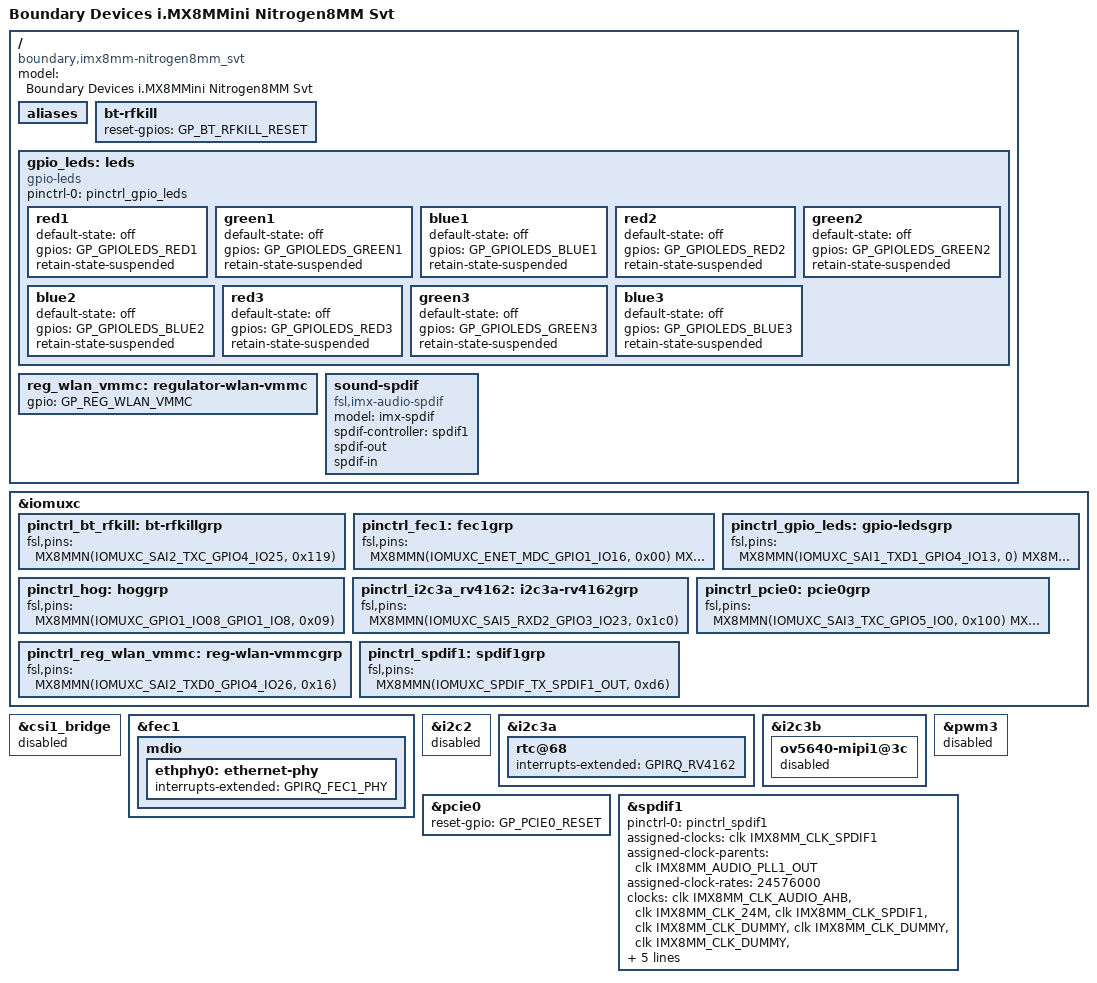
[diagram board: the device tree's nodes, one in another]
// SPDX-License-Identifier: (GPL-2.0+ OR MIT)
/*
 * Copyright 2022 Boundary Devices
 */
#define TOUCHSCREEN_I2C_BUS	i2c3b
#include "imx8mm-nitrogen8mm.dts"

&iomuxc {
	/delete-node/ ecspi2-mcp2515tgrp;

	pinctrl_bt_rfkill: bt-rfkillgrp {
		fsl,pins = <
#undef GP_BT_RFKILL_RESET
#define GP_BT_RFKILL_RESET	<&gpio4 25 GPIO_ACTIVE_LOW>
			MX8MMN(IOMUXC_SAI2_TXC_GPIO4_IO25, 0x119)
		>;
	};

	pinctrl_fec1: fec1grp {
		fsl,pins = <
			/* PAD_CTL_ODE is screwy on 8mm mini, avoid it */
#define GP_MII_MDC	<&gpio1 16 GPIO_PULSE_HIGH>
			MX8MMN(IOMUXC_ENET_MDC_GPIO1_IO16, 0x00)
#define GP_MII_MDIO	<&gpio1 17 GPIO_ACTIVE_HIGH>
			MX8MMN(IOMUXC_ENET_MDIO_GPIO1_IO17, 0x00)
			MX8MMN(IOMUXC_ENET_RD0_ENET1_RGMII_RD0, 0x91)
			MX8MMN(IOMUXC_ENET_RD1_ENET1_RGMII_RD1, 0x91)
			MX8MMN(IOMUXC_ENET_RD2_ENET1_RGMII_RD2, 0x91)
			MX8MMN(IOMUXC_ENET_RD3_ENET1_RGMII_RD3, 0x91)
			MX8MMN(IOMUXC_ENET_RXC_ENET1_RGMII_RXC, 0x91)
			MX8MMN(IOMUXC_ENET_RX_CTL_ENET1_RGMII_RX_CTL, 0x91)
			MX8MMN(IOMUXC_ENET_TD0_ENET1_RGMII_TD0, 0x1f)
			MX8MMN(IOMUXC_ENET_TD1_ENET1_RGMII_TD1, 0x1f)
			MX8MMN(IOMUXC_ENET_TD2_ENET1_RGMII_TD2, 0x1f)
			MX8MMN(IOMUXC_ENET_TD3_ENET1_RGMII_TD3, 0x1f)
			MX8MMN(IOMUXC_ENET_TXC_ENET1_RGMII_TXC, 0x1f)
			MX8MMN(IOMUXC_ENET_TX_CTL_ENET1_RGMII_TX_CTL, 0x1f)
			MX8MMN(IOMUXC_SAI3_TXFS_GPT1_CAPTURE2, 0x0)
			MX8MMN(IOMUXC_I2C2_SDA_ENET1_1588_EVENT1_OUT, 0x0)
#undef GP_FEC1_RESET
#define GP_FEC1_RESET	<&gpio1 3 GPIO_ACTIVE_LOW>
			MX8MMN(IOMUXC_GPIO1_IO03_GPIO1_IO3, 0x159)
#undef GPIRQ_FEC1_PHY
#define GPIRQ_FEC1_PHY	<&gpio1 5 IRQ_TYPE_LEVEL_LOW>
			MX8MMN(IOMUXC_GPIO1_IO05_GPIO1_IO5, 0x159)
		>;
	};

	pinctrl_gpio_leds: gpio-ledsgrp {
	        fsl,pins = <
#define GP_GPIOLEDS_RED1        <&gpio4 13 (GPIO_OPEN_DRAIN | GPIO_ACTIVE_LOW)>
	                MX8MMN(IOMUXC_SAI1_TXD1_GPIO4_IO13, 0)
#define GP_GPIOLEDS_GREEN1      <&gpio4 14 (GPIO_OPEN_DRAIN | GPIO_ACTIVE_LOW)>
	                MX8MMN(IOMUXC_SAI1_TXD2_GPIO4_IO14, 0)
#define GP_GPIOLEDS_BLUE1       <&gpio4 15 (GPIO_OPEN_DRAIN | GPIO_ACTIVE_LOW)>
	                MX8MMN(IOMUXC_SAI1_TXD3_GPIO4_IO15, 0)

#define GP_GPIOLEDS_RED2        <&gpio4 16 (GPIO_OPEN_DRAIN | GPIO_ACTIVE_LOW)>
	                MX8MMN(IOMUXC_SAI1_TXD4_GPIO4_IO16, 0)
#define GP_GPIOLEDS_GREEN2      <&gpio4 17 (GPIO_OPEN_DRAIN | GPIO_ACTIVE_LOW)>
	                MX8MMN(IOMUXC_SAI1_TXD5_GPIO4_IO17, 0)
#define GP_GPIOLEDS_BLUE2       <&gpio4 18 (GPIO_OPEN_DRAIN | GPIO_ACTIVE_LOW)>
	                MX8MMN(IOMUXC_SAI1_TXD6_GPIO4_IO18, 0)

#define GP_GPIOLEDS_RED3        <&gpio4 19 (GPIO_OPEN_DRAIN | GPIO_ACTIVE_LOW)>
	                MX8MMN(IOMUXC_SAI1_TXD7_GPIO4_IO19, 0)
#define GP_GPIOLEDS_GREEN3      <&gpio4 0 (GPIO_OPEN_DRAIN | GPIO_ACTIVE_LOW)>
	                MX8MMN(IOMUXC_SAI1_RXFS_GPIO4_IO0, 0)
#define GP_GPIOLEDS_BLUE3       <&gpio4 1 (GPIO_OPEN_DRAIN | GPIO_ACTIVE_LOW)>
	                MX8MMN(IOMUXC_SAI1_RXC_GPIO4_IO1, 0)
	        >;
	};

	pinctrl_hog: hoggrp {
		fsl,pins = <
			MX8MMN(IOMUXC_GPIO1_IO08_GPIO1_IO8, 0x09)
		>;
	};

	pinctrl_i2c3a_rv4162: i2c3a-rv4162grp {
		fsl,pins = <
#undef GPIRQ_RV4162
#define GPIRQ_RV4162		<&gpio3 23 IRQ_TYPE_LEVEL_LOW>
			MX8MMN(IOMUXC_SAI5_RXD2_GPIO3_IO23, 0x1c0)
		>;
	};

	pinctrl_pcie0: pcie0grp {
		fsl,pins = <
#undef GP_PCIE0_RESET
#define GP_PCIE0_RESET		<&gpio5 0 GPIO_ACTIVE_LOW>
			MX8MMN(IOMUXC_SAI3_TXC_GPIO5_IO0, 0x100)
#define GP_PCIE0_DISABLE	<&gpio1 4 GPIO_ACTIVE_LOW>
			MX8MMN(IOMUXC_GPIO1_IO04_GPIO1_IO4, 0x100)
		>;
	};

	pinctrl_reg_wlan_vmmc: reg-wlan-vmmcgrp {
		fsl,pins = <
#undef GP_REG_WLAN_VMMC
#define GP_REG_WLAN_VMMC	<&gpio4 26 GPIO_ACTIVE_HIGH>
			MX8MMN(IOMUXC_SAI2_TXD0_GPIO4_IO26, 0x16)
		>;
	};

	/delete-node/ sai2grp;
	/delete-node/ sai5grp;

	pinctrl_spdif1: spdif1grp {
		fsl,pins = <
			MX8MMN(IOMUXC_SPDIF_TX_SPDIF1_OUT, 0xd6)
		>;
	};
};

/ {
	model = "Boundary Devices i.MX8MMini Nitrogen8MM Svt";
	compatible = "boundary,imx8mm-nitrogen8mm_svt", "fsl,imx8mm";

	aliases {
		/delete-property/ sai2;
		/delete-property/ sai5;
		/delete-property/ spi1;
	};

	bt-rfkill {
		reset-gpios = GP_BT_RFKILL_RESET;
	};

	gpio_leds: leds {
                compatible = "gpio-leds";
                pinctrl-names = "default";
                pinctrl-0 = <&pinctrl_gpio_leds>;

                red1 {
                        default-state = "off";
                        gpios = GP_GPIOLEDS_RED1;
                        retain-state-suspended;
                };

                green1 {
                        default-state = "off";
                        gpios = GP_GPIOLEDS_GREEN1;
                        retain-state-suspended;
                };

                blue1 {
                        default-state = "off";
                        gpios = GP_GPIOLEDS_BLUE1;
                        retain-state-suspended;
                };

                red2 {
                        default-state = "off";
                        gpios = GP_GPIOLEDS_RED2;
                        retain-state-suspended;
                };

                green2 {
                        default-state = "off";
                        gpios = GP_GPIOLEDS_GREEN2;
                        retain-state-suspended;
                };

                blue2 {
                        default-state = "off";
                        gpios = GP_GPIOLEDS_BLUE2;
                        retain-state-suspended;
                };

                red3 {
                        default-state = "off";
                        gpios = GP_GPIOLEDS_RED3;
                        retain-state-suspended;
                };

                green3 {
                        default-state = "off";
                        gpios = GP_GPIOLEDS_GREEN3;
                        retain-state-suspended;
                };

                blue3 {
                        default-state = "off";
                        gpios = GP_GPIOLEDS_BLUE3;
                        retain-state-suspended;
		};
	};

	reg_wlan_vmmc: regulator-wlan-vmmc {
		gpio = GP_REG_WLAN_VMMC;
	};

	sound-spdif {
		compatible = "fsl,imx-audio-spdif";
		model = "imx-spdif";
		spdif-controller = <&spdif1>;
		spdif-out;
		spdif-in;
	};
};

&csi1_bridge {
	status = "disabled";
};

/delete-node/ &ecspi2;

&fec1 {
#if 0
	phy-reset-gpios = GP_FEC1_RESET;
#endif

	mdio {
		ethphy0: ethernet-phy {
			interrupts-extended = GPIRQ_FEC1_PHY;
		};
	};
};

&i2c2 {
	status = "disabled";
};

&i2c3a {
	rtc@68 {
		interrupts-extended = GPIRQ_RV4162;
	};
};

&i2c3b {
	ov5640-mipi1@3c {
		status = "disabled";
	};
};

&pcie0 {
	reset-gpio = GP_PCIE0_RESET;
};

&pwm3 {
	status = "disabled";
};

/delete-node/ &sai2;
/delete-node/ &sai5;

&spdif1 {
	pinctrl-names = "default";
	pinctrl-0 = <&pinctrl_spdif1>;
	assigned-clocks = <&clk IMX8MM_CLK_SPDIF1>;
	assigned-clock-parents = <&clk IMX8MM_AUDIO_PLL1_OUT>;
	assigned-clock-rates = <24576000>;
	clocks = <&clk IMX8MM_CLK_AUDIO_AHB>, <&clk IMX8MM_CLK_24M>,
		<&clk IMX8MM_CLK_SPDIF1>, <&clk IMX8MM_CLK_DUMMY>,
		<&clk IMX8MM_CLK_DUMMY>, <&clk IMX8MM_CLK_DUMMY>,
		<&clk IMX8MM_CLK_AUDIO_AHB>, <&clk IMX8MM_CLK_DUMMY>,
		<&clk IMX8MM_CLK_DUMMY>, <&clk IMX8MM_CLK_DUMMY>,
		<&clk IMX8MM_AUDIO_PLL1_OUT>, <&clk IMX8MM_AUDIO_PLL2_OUT>;
	clock-names = "core", "rxtx0", "rxtx1", "rxtx2", "rxtx3",
		"rxtx4", "rxtx5", "rxtx6", "rxtx7", "spba", "pll8k", "pll11k";
	status = "okay";
};
